# QN908X register map
Vendor: nxp.com; File version: 1.0
CPU: CM4 r0p1, little endian, MPU, FPU, VTOR, 3 interrupt priority bits
Registers are 32-bit, read-write, reset 0x0 unless marked. A register's access mark holds for its fields unless they carry their own. Offsets are from the block's base; [hi:lo] are bit positions.

## RTC
Base 0x4000B000
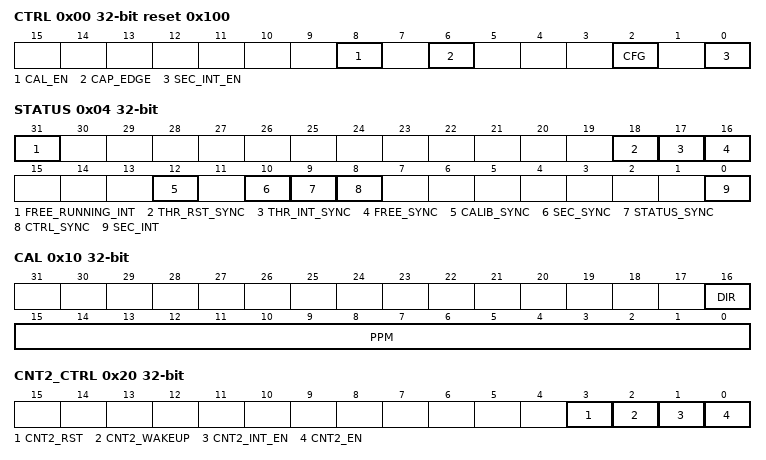
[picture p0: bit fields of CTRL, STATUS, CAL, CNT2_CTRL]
0x00 CTRL reset 0x100 — RTC control register
  [8] CAL_EN — Calibration enable
  [6] CAP_EDGE — capture active edge selection
    0=POSEDGE (capture the posedge of input); 1=NEGEDGE (capture the negedge of input)
  [2] CFG — RTC second configuration control. This bit is self-cleared after synchronization
  [0] SEC_INT_EN — RTC second interrupt enable
0x04 STATUS — RTC status register
  [31] FREE_RUNNING_INT ro — Free running interrupt status.
  [18] THR_RST_SYNC ro — Free running counter Reset Threshold Register synchronization busy indicator
  [17] THR_INT_SYNC ro — Free running counter interrupt Threshold Register synchronization busy indicator
  [16] FREE_SYNC ro — Free running counter control Register synchronization busy indicator
  [12] CALIB_SYNC ro — Calibration Register synchronization busy indicator
  [10] SEC_SYNC ro — Second configuration Register synchronization busy indicator
  [9] STATUS_SYNC ro — Status Register synchronization busy indicator
  [8] CTRL_SYNC ro — Control Register synchronization busy indicator
  [0] SEC_INT rw-once — Second interrupt flag
0x08 SEC — RTC second register
  [31:0] SEC — Second configuration register.
0x10 CAL — RTC calibration register
  [16] DIR — RTC calibration direction indicator
    0=FORWARD (forward calibrate); 1=BACKWARD (backward calibrate)
  [15:0] PPM — RTC calibration ppm value the precision is 1 ppm.
0x14 CNT_VAL ro — RTC count value register
  [14:0] CNT — RTC counter current value read only.
0x20 CNT2_CTRL — Free running control register
  [3] CNT2_RST — 1 to enable free running reset
  [2] CNT2_WAKEUP — 1 to enable free running wakeup
  [1] CNT2_INT_EN — 1 to enable free running interrupt
  [0] CNT2_EN — 1 to enable free running counter
0x24 THR_INT reset 0xF000000 — interrupt threshold of free running counter register
  [31:0] THR_INT — The Threshold of free running counter is to generate free running interrupt.
0x28 THR_RST reset 0xFF000000 — reset threshold of free running counter register
  [31:0] THR_RST — The Threshold of free running counter is to generate free running reset.
0x2C CNT2 ro — free running count value
  [31:0] CNT2 — The current value of free running counter

## AGC
Base 0x4000C000
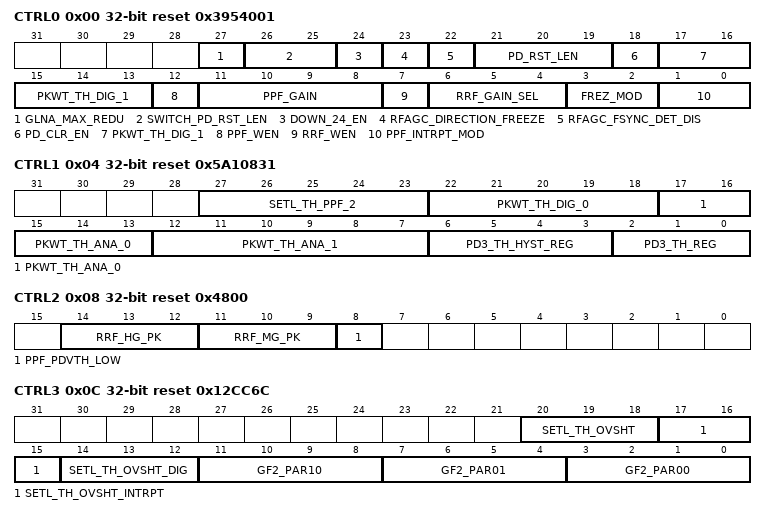
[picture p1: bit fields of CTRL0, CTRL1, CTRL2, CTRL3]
0x00 CTRL0 reset 0x3954001 — AGC control register 0
  [27] GLNA_MAX_REDU — Lna max gain reduce 12dbm0bdisable 1benable
  [26:25] SWITCH_PD_RST_LEN — Pd disable time when direction found rfagc reset00b2us 01b4us 10b8us 11b16us
  [24] DOWN_24_EN — Lna decrease 24dbm0bdisable 1benable
  [23] RFAGC_DIRECTION_FREEZE — Use to disable rfagc gain adjust when switching antenna at direction found mode0b rfagc enable 1brfagc disable
  [22] RFAGC_FSYNC_DET_DIS — Use to control rfagc gain adjust0brfagc stops when sync 1brfagc always on
  [21:19] PD_RST_LEN — Pd disable time when reset0h0us 1h8us 2h16us 7h56us
  [18] PD_CLR_EN — Force clear analog PD
  [17:13] PKWT_TH_DIG_1 — PKWT_TH_DIG + PKWT_TH_DIG_ADD in ccode
  [12] PPF_WEN — Ppf gain write enable
  [11:8] PPF_GAIN — PPF gain controlGain=36-3*PPF_GAIN
  [7] RRF_WEN — Lna gain write enable
  [6:4] RRF_GAIN_SEL — LNA gain controlGAIN=26-12*LNA_GAIN_SEL
  [3:2] FREZ_MOD — Control whether fsm can restore last value when correalation trigh happens
  [1:0] PPF_INTRPT_MOD — Control whether fsm can interrupt
0x04 CTRL1 reset 0x5A10831 — AGC control register 1
  [27:23] SETL_TH_PPF_2 — SETL_TH_PPF_2 + DLY_DIG 1 in ccode
  [22:18] PKWT_TH_DIG_0 — PKWT_TH_DIG in ccode
  [17:13] PKWT_TH_ANA_0 — PKWT_TH_ANA in ccode
  [12:7] PKWT_TH_ANA_1 — PKWT_TH_ANA + PKWT_TH_ANA_ADD
  [6:3] PD3_TH_HYST_REG — Desired upper boundary
  [2:0] PD3_TH_REG — Pd3 threshold
0x08 CTRL2 reset 0x4800 — AGC control register 2
  [14:12] RRF_HG_PK — LNA high gain peak detect threshold selectAMP=(100-8* LNA_HG_PK)mv
  [11:9] RRF_MG_PK — LNA medium gain peak detect threshold selectAMP=(400-25* LNA_MG_PK)mv
  [8] PPF_PDVTH_LOW — PPF peak detect threshold select
0x0C CTRL3 reset 0x12CC6C — AGC control register 3
  [20:18] SETL_TH_OVSHT, [17:15] SETL_TH_OVSHT_INTRPT, [14:12] SETL_TH_OVSHT_DIG, [11:8] GF2_PAR10, [7:4] GF2_PAR01, [3:0] GF2_PAR00
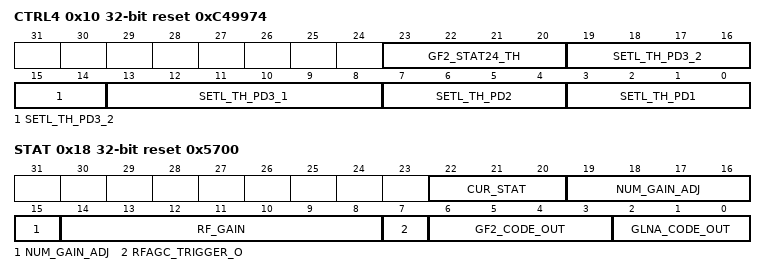
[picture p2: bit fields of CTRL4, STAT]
0x10 CTRL4 reset 0xC49974 — AGC control register 4
  [23:20] GF2_STAT24_TH, [19:14] SETL_TH_PD3_2, [13:8] SETL_TH_PD3_1, [7:4] SETL_TH_PD2, [3:0] SETL_TH_PD1
0x14 CTRL5 — AGC control register 5
  [3:0] TEST_CTRL
0x18 STAT ro reset 0x5700 — AGC status register
  [22:20] CUR_STAT, [19:15] NUM_GAIN_ADJ, [14:8] RF_GAIN, [7] RFAGC_TRIGGER_O, [6:3] GF2_CODE_OUT, [2:0] GLNA_CODE_OUT
